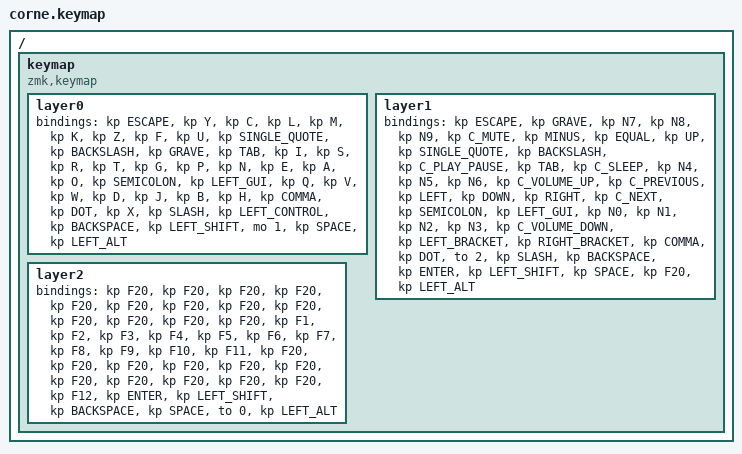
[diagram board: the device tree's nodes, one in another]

  /*
  * Copyright (c) 2020 The ZMK Contributors
  *
  * SPDX-License-Identifier: MIT
  */

  #include <behaviors.dtsi>
  #include <dt-bindings/zmk/keys.h>
  #include <dt-bindings/zmk/bt.h>
  #include <dt-bindings/zmk/ext_power.h>

  / {
    keymap {
      compatible = "zmk,keymap";
  layer0 {
          bindings = <
          &kp ESCAPE &kp Y &kp C &kp L &kp M &kp K &kp Z &kp F &kp U &kp SINGLE_QUOTE &kp BACKSLASH &kp GRAVE &kp TAB &kp I &kp S &kp R &kp T &kp G &kp P &kp N &kp E &kp A &kp O &kp SEMICOLON &kp LEFT_GUI &kp Q &kp V &kp W &kp D &kp J &kp B &kp H &kp COMMA &kp DOT &kp X &kp SLASH &kp LEFT_CONTROL  &kp BACKSPACE &kp LEFT_SHIFT &mo 1 &kp SPACE &kp LEFT_ALT
          >;
        };layer1 {
          bindings = <
          &kp ESCAPE &kp GRAVE &kp N7 &kp N8 &kp N9 &kp C_MUTE &kp MINUS &kp EQUAL &kp UP &kp SINGLE_QUOTE &kp BACKSLASH &kp C_PLAY_PAUSE &kp TAB &kp C_SLEEP &kp N4 &kp N5 &kp N6 &kp C_VOLUME_UP &kp C_PREVIOUS &kp LEFT &kp DOWN &kp RIGHT &kp C_NEXT &kp SEMICOLON &kp LEFT_GUI &kp N0 &kp N1 &kp N2 &kp N3 &kp C_VOLUME_DOWN &kp LEFT_BRACKET &kp RIGHT_BRACKET &kp COMMA &kp DOT &to 2 &kp SLASH &kp BACKSPACE &kp ENTER &kp LEFT_SHIFT &kp SPACE &kp F20 &kp LEFT_ALT
          >;
        };layer2 {
          bindings = <
          &kp F20 &kp F20 &kp F20 &kp F20 &kp F20 &kp F20 &kp F20 &kp F20 &kp F20 &kp F20 &kp F20 &kp F20 &kp F20 &kp F1 &kp F2 &kp F3 &kp F4 &kp F5 &kp F6 &kp F7 &kp F8 &kp F9 &kp F10 &kp F11 &kp F20 &kp F20 &kp F20 &kp F20 &kp F20 &kp F20 &kp F20 &kp F20 &kp F20 &kp F20 &kp F20 &kp F12 &kp ENTER &kp LEFT_SHIFT &kp BACKSPACE &kp SPACE &to 0 &kp LEFT_ALT
          >;
        };
    };
  };
  
